# nrf7120E_enga_application register map
Vendor: Nordic Semiconductor; Series: nrf71; File version: 1
CPU: CM33 r0p4, little endian, MPU, FPU, 3 interrupt priority bits, 270 interrupts, 4 SAU regions
Registers are 32-bit, read-write, reset 0x0 unless marked. A register's access mark holds for its fields unless they carry their own. Offsets are from the block's base; [hi:lo] are bit positions; 'fields as' and 'values as' point back to an identical list.

## CPUC_S — CPU control
Base 0xE0080000
0x100 EVENTS_FPUIOC — An invalid operation exception has occurred in the FPU.
  [0] EVENTS_FPUIOC
    0=NotGenerated (Event not generated); 1=Generated (Event generated)
0x104 EVENTS_FPUDZC — A floating-point divide-by-zero exception has occurred in the FPU.
  [0] EVENTS_FPUDZC
    values as EVENTS_FPUIOC.EVENTS_FPUIOC
0x108 EVENTS_FPUOFC — A floating-point overflow exception has occurred in the FPU.
  [0] EVENTS_FPUOFC
    values as EVENTS_FPUIOC.EVENTS_FPUIOC
0x10C EVENTS_FPUUFC — A floating-point underflow exception has occurred in the FPU.
  [0] EVENTS_FPUUFC
    values as EVENTS_FPUIOC.EVENTS_FPUIOC
0x110 EVENTS_FPUIXC — A floating-point inexact exception has occurred in the FPU.
  [0] EVENTS_FPUIXC
    values as EVENTS_FPUIOC.EVENTS_FPUIOC
0x114 EVENTS_FPUIDC — A floating-point input denormal exception has occurred in the FPU.
  [0] EVENTS_FPUIDC
    values as EVENTS_FPUIOC.EVENTS_FPUIOC
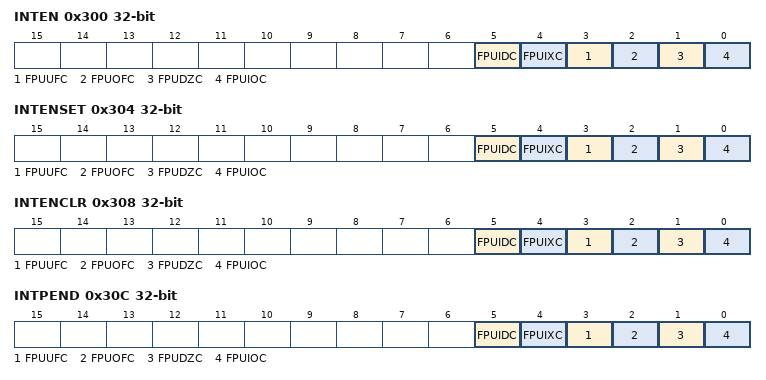
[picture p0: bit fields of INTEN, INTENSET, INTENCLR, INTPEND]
0x300 INTEN — Enable or disable interrupt
  [all] fields
    0=Disabled; 1=Enabled
  [5] FPUIDC — Enable or disable interrupt for event FPUIDC
  [4] FPUIXC — Enable or disable interrupt for event FPUIXC
  [3] FPUUFC — Enable or disable interrupt for event FPUUFC
  [2] FPUOFC — Enable or disable interrupt for event FPUOFC
  [1] FPUDZC — Enable or disable interrupt for event FPUDZC
  [0] FPUIOC — Enable or disable interrupt for event FPUIOC
0x304 INTENSET — Enable interrupt
  [all] fields
    on read: 0=Disabled (Read: Disabled); 1=Enabled (Read: Enabled) | on write: 1=Set (Enable)
  [5] FPUIDC write-1-sets — Write '1' to enable interrupt for event FPUIDC
  [4] FPUIXC write-1-sets — Write '1' to enable interrupt for event FPUIXC
  [3] FPUUFC write-1-sets — Write '1' to enable interrupt for event FPUUFC
  [2] FPUOFC write-1-sets — Write '1' to enable interrupt for event FPUOFC
  [1] FPUDZC write-1-sets — Write '1' to enable interrupt for event FPUDZC
  [0] FPUIOC write-1-sets — Write '1' to enable interrupt for event FPUIOC
0x308 INTENCLR — Disable interrupt
  [all] fields
    on read: 0=Disabled (Read: Disabled); 1=Enabled (Read: Enabled) | on write: 1=Clear (Disable)
  [5] FPUIDC write-1-clears — Write '1' to disable interrupt for event FPUIDC
  [4] FPUIXC write-1-clears — Write '1' to disable interrupt for event FPUIXC
  [3] FPUUFC write-1-clears — Write '1' to disable interrupt for event FPUUFC
  [2] FPUOFC write-1-clears — Write '1' to disable interrupt for event FPUOFC
  [1] FPUDZC write-1-clears — Write '1' to disable interrupt for event FPUDZC
  [0] FPUIOC write-1-clears — Write '1' to disable interrupt for event FPUIOC
0x30C INTPEND ro — Pending interrupts
  [all] fields
    on read: 0=NotPending (Read: Not pending); 1=Pending (Read: Pending)
  [5] FPUIDC — Read pending status of interrupt for event FPUIDC
  [4] FPUIXC — Read pending status of interrupt for event FPUIXC
  [3] FPUUFC — Read pending status of interrupt for event FPUUFC
  [2] FPUOFC — Read pending status of interrupt for event FPUOFC
  [1] FPUDZC — Read pending status of interrupt for event FPUDZC
  [0] FPUIOC — Read pending status of interrupt for event FPUIOC
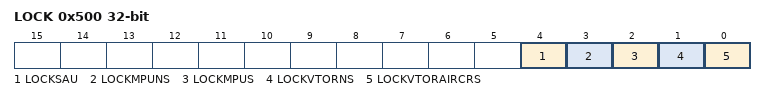
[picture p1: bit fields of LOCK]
0x500 LOCK — Register to lock the certain parts of the CPU from being modified.
  [4] LOCKSAU — Locks the Security Attribution Unit (SAU)
    0=NotLocked (SAU registers can be changed.); 1=Locked (Prevents changes to SAU registers.)
  [3] LOCKMPUNS — Locks the Memory Protection Unit (MPU) for non secure mode.
    0=NotLocked (MPU registers can be changed.); 1=Locked (Prevents changes to MPU registers.)
  [2] LOCKMPUS — Locks the Memory Protection Unit (MPU) for secure mode.
    values as LOCKMPUNS
  [1] LOCKVTORNS — Locks the Vector table Offset Register (VTOR) for non-secure mode.
    0=NotLocked (VTOR can be changed.); 1=Locked (Prevents changes to VTOR.)
  [0] LOCKVTORAIRCRS — Locks both the Vector table Offset Register (VTOR) and Application Interrupt and Reset Control Register (AIRCR) for secure mode.
    0=NotLocked (Both VTOR and AIRCR can be changed.); 1=Locked (Prevents changes to both VTOR and AIRCR.)
0x504 CPUID ro — The identifier for the CPU in this subsystem.
  [31:0] CPUID — The CPU identifier.

## Notices in the file
Copyright (c) 2010 - 2026, Nordic Semiconductor ASA All rights reserved.
SPDX-License-Identifier: BSD-3-Clause
Redistribution and use in source and binary forms, with or without
modification, are permitted provided that the following conditions are met:
1. Redistributions of source code must retain the above copyright notice, this
list of conditions and the following disclaimer.
2. Redistributions in binary form must reproduce the above copyright
notice, this list of conditions and the following disclaimer in the
documentation and/or other materials provided with the distribution.
3. Neither the name of Nordic Semiconductor ASA nor the names of its
contributors may be used to endorse or promote products derived from this
software without specific prior written permission.
THIS SOFTWARE IS PROVIDED BY THE COPYRIGHT HOLDERS AND CONTRIBUTORS "AS IS"
AND ANY EXPRESS OR IMPLIED WARRANTIES, INCLUDING, BUT NOT LIMITED TO, THE
IMPLIED WARRANTIES OF MERCHANTABILITY, AND FITNESS FOR A PARTICULAR PURPOSE
ARE DISCLAIMED. IN NO EVENT SHALL NORDIC SEMICONDUCTOR ASA OR CONTRIBUTORS BE
LIABLE FOR ANY DIRECT, INDIRECT, INCIDENTAL, SPECIAL, EXEMPLARY, OR
CONSEQUENTIAL DAMAGES (INCLUDING, BUT NOT LIMITED TO, PROCUREMENT OF
SUBSTITUTE GOODS OR SERVICES; LOSS OF USE, DATA, OR PROFITS; OR BUSINESS
INTERRUPTION) HOWEVER CAUSED AND ON ANY THEORY OF LIABILITY, WHETHER IN
CONTRACT, STRICT LIABILITY, OR TORT (INCLUDING NEGLIGENCE OR OTHERWISE)
ARISING IN ANY WAY OUT OF THE USE OF THIS SOFTWARE, EVEN IF ADVISED OF THE
POSSIBILITY OF SUCH DAMAGE.
